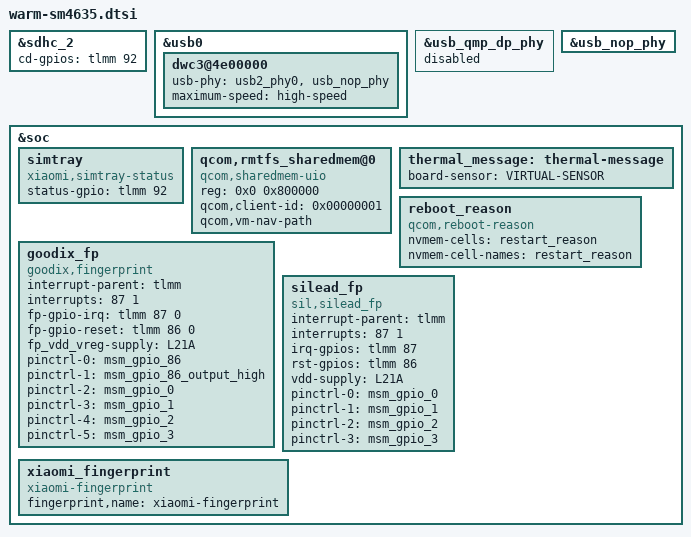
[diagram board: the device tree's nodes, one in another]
/* And public attribution of longcheer platforms */
#include "longcheer-sm4635-common.dtsi"
#include "warm-pinctrl.dtsi"

&sdhc_2 {
	cd-gpios = <&tlmm 92 GPIO_ACTIVE_HIGH>;
};

&usb0 {
	dwc3@4e00000 {
		usb-phy = <&usb2_phy0>, <&usb_nop_phy>;
		maximum-speed = "high-speed";
	};
};

&usb_qmp_dp_phy {
	status = "disabled";
};

&usb_nop_phy {
	status = "okay";
};

&soc {
	/*add simtray status*/
	simtray {
		compatible = "xiaomi,simtray-status";
		status-gpio = <&tlmm 92 0x00>;
	};

	qcom,rmtfs_sharedmem@0 {
		compatible = "qcom,sharedmem-uio";
		reg = <0x0 0x800000>;
		reg-names = "rmtfs";
		qcom,client-id = <0x00000001>;
		qcom,vm-nav-path;
	};

	thermal_message: thermal-message {
		board-sensor = "VIRTUAL-SENSOR";
	};

	reboot_reason {
		compatible = "qcom,reboot-reason";
		nvmem-cells = <&restart_reason>;
		nvmem-cell-names = "restart_reason";
	};

    goodix_fp: goodix_fp {
        compatible = "goodix,fingerprint";
        interrupt-parent = <&tlmm>;
        interrupts = <87 1>;
        fp-gpio-irq = <&tlmm 87 0>;
        fp-gpio-reset = <&tlmm 86 0>;
        fp_vdd_vreg-supply = <&L21A>;
        pinctrl-names = "goodix_reset_outputlow",
                        "goodix_reset_outputhigh",
                        "fp_spi_miso_active",
                        "fp_spi_mosi_active",
                        "fp_spi_clk_active",
                        "fp_spi_cs_active";
        pinctrl-0 = <&msm_gpio_86>;
        pinctrl-1 = <&msm_gpio_86_output_high>;
        pinctrl-2 = <&msm_gpio_0>;
        pinctrl-3 = <&msm_gpio_1>;
        pinctrl-4 = <&msm_gpio_2>;
        pinctrl-5 = <&msm_gpio_3>;
        status = "okay";
    };

    silead_fp: silead_fp {
        compatible = "sil,silead_fp";
        interrupt-parent = <&tlmm>;
        interrupts = <87 1>;
        irq-gpios = <&tlmm 87 0>;
        rst-gpios = <&tlmm 86 0>;
        vdd-supply = <&L21A>;
        pinctrl-names = "fp_spi_miso_active",
                        "fp_spi_mosi_active",
                        "fp_spi_clk_active",
                        "fp_spi_cs_active";
        pinctrl-0 = <&msm_gpio_0>;
        pinctrl-1 = <&msm_gpio_1>;
        pinctrl-2 = <&msm_gpio_2>;
        pinctrl-3 = <&msm_gpio_3>;
        status = "okay";
    };

    xiaomi_fingerprint {
        compatible = "xiaomi-fingerprint";
        status = "ok";
        fingerprint,name = "xiaomi-fingerprint";
    };
};
